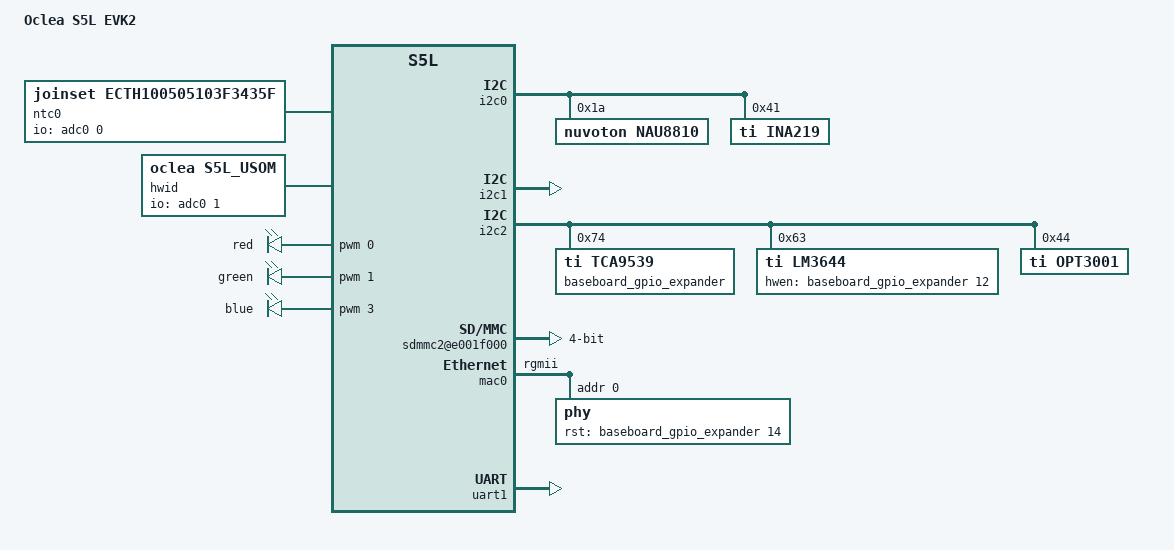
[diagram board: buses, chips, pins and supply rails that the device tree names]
/dts-v1/;
/include/ "ambarella-s5l.dtsi"
/include/ "s5l_oclea_cma.dtsi"
/include/ "s5l_oclea_private_evk2.dtsi"
/ {
 model = "Oclea S5L EVK2";
 compatible = "ambarella,s5l_oclea", "ambarella,s5l";
 oclea-vin-version = <1>;
 chosen {
  bootargs = "console=ttyS0 noinitrd root=##ROOT_DEVICE## rw rootfstype=ext4 rootwait init=/sbin/init";
 };
 apb@e8000000 {
  ntc0: ntc0 {
   compatible = "joinset,ecth100505103f3435f";
   pullup-uv = <3300000>;
   pullup-ohm = <10000>;
   pulldown-ohm = <0>;
   io-channels = <&adc0 0>;
   alias-name = "main-ntc";
   #thermal-sensor-cells = <0>;
  };
  hwid {
   compatible = "oclea,s5l_uSOM";
   pullup-mv = <3300>;
   io-channels = <&adc0 1>;
   alias-name = "hwid";
  };
  adc0: adc@e801d000 {
   amb,channels-used = <0x0a>;
   #io-channel-cells = <1>;
  };
  i2c0: i2c@e8003000 {
   status = "ok";
   nau8810: codec@1a {
    compatible = "nuvoton,nau8810";
    #sound-dai-cells = <0>;
    reg = <0x1a>;
   };
   ina219: ina219@41 {
    compatible = "ti,ina219";
    reg = <0x41>;
    shunt-resistor = <100000>;
   };
  };
  i2c1: i2c@e8001000 {
   status = "ok";
  };
  i2c2: i2c@e8007000 {
   status = "ok";
   baseboard_gpio_expander: tca9539@74 {
    compatible = "ti,tca9539";
    reg = <0x74>;
    gpio-controller;
    interrupt-parent = <&gpio>;
    interrupt-controller;
    #gpio-cells = <2>;
    gpio-line-names =
     "", "", "", "", "", "", "", "",
     "", "bt-en", "", "ir-led-gpio", "ir-led-en", "rs485-re", "eth-reset", "";
    port-0-0 {
     gpios = <0 0>;
     output-low;
    };
    port-0-1 {
     gpios = <1 0>;
     output-low;
    };
    port-0-2 {
     gpios = <2 0>;
     output-low;
    };
    port-0-3 {
     gpios = <3 0>;
     output-low;
    };
    port-0-4 {
     gpios = <4 0>;
     output-low;
    };
    port-0-5 {
     gpios = <5 0>;
     output-low;
    };
    port-0-6 {
     gpios = <6 0>;
     output-low;
    };
    port-0-7 {
     gpios = <7 0>;
     output-low;
    };
    port-1-0 {
     gpios = <8 0>;
     output-low;
    };
    port-1-1 {
     gpios = <9 0>;
     output-low;
    };
    port-1-2 {
     gpios = <10 0>;
     output-low;
    };
    port-1-3 {
     gpios = <11 0>;
     output-low;
    };
    port-1-4 {
     gpios = <12 0>;
     output-low;
    };
    port-1-5 {
     gpios = <13 0>;
     output-low;
    };
    port-1-6 {
     gpios = <14 0>;
     output-low;
    };
    port-1-7 {
     gpios = <15 0>;
     output-low;
    };
   };
   lm3644: ir_led@63 {
    compatible = "ti,lm3644";
    reg = <0x63>;
    lm3644,hwen-gpio = <&baseboard_gpio_expander 12 0>;
    lm3644,flash-timeout = <0x1>;
    lm3644,pass-mode;
    lm3644,disable-tx;
   };
   opt3001@44 {
    compatible = "ti,opt3001";
    reg = <0x44>;
   };
  };
  ir@e8006000 {
   status = "disabled";
  };
  pwm: pwm@e8008000 {
   pinctrl-names = "default";
   pinctrl-0 = <&pwm0_pins_b>, <&pwm1_pins_c>, <&pwm3_pins_c>;
  };
  pinctrl: pinctrl@e8009000 {
   enet_2nd_ref_clk_pin: enet_2nd_ref_clk@0 {
     reg = <0>;
     amb,pinmux-ids = <0x1044>;
   };
   sdmmc2_rst_pin: sdmmc2_rst@0 {
    reg = <0>;
    amb,pinmux-ids = <0x2070>;
   };
  };
 };
 ahb@e0000000 {
  sdmmc0@e0002000 {
   amb,emmc-boot;
   amb,sd-force-1_8v;
   amb,fixed-cd = <1>;
  };
  sdmmc2@e001f000 {
   status = "ok";
   pinctrl-0 = <&sdmmc2_pins_4bit &sdmmc2_cd_pin &sdmmc2_rst_pin>;
   bus-width = <4>;
   no-1-8-v;
  };
  mac0: ethernet@e000e000 {
   amb,tx-clk-invert;
   amb,override-phy-type;
   pinctrl-0 = <&rgmii_pins &rgmii_mdio_pins &enet_2nd_ref_clk_pin>;
   phy-mode = "rgmii";
   phy@0 {
    reg = <0>;
    rst-gpios = <&baseboard_gpio_expander 14 0>;
    rst-gpio-delay = <100>;
   };
  };
  nand0: nand@e0001000 {
   status = "disabled";
  };
  spi0: spi@e0020000 {
   status = "disabled";
  };
  spi2: spi@e0022000 {
   status = "disabled";
  };
  uart1: uart@e0032000 {
      status = "ok";
  };
  hdmi@e0013000 {
   amb,i2c-adapter = <1>;
   pinctrl-names = "default";
   pinctrl-0 = <&hdmi_pin>;
  };
 };
 pwm-leds {
        compatible = "pwm-leds";
        red {
            label = "red";
            pwms = <&pwm 0 40000 0>;
            max-brightness = <255>;
        };
        green {
            label = "green";
            pwms = <&pwm 1 40000 0>;
            max-brightness = <255>;
        };
        blue {
            label = "blue";
            pwms = <&pwm 3 40000 0>;
            max-brightness = <255>;
        };
    };
 rct@ec170000 {
  usbphy: usbphy@ec170050 {
   amb,ocp-polarity = <1>;
   amb,phy-route = "device";
   pinctrl-names = "default";
   pinctrl-0 = <&usb_host0_pins>;
   md-gpios = <&gpio 13 0x0>;
  };
 };
 iav {
  vinc0 {
  };
  vinc1 {
  };
  hwtimer {
   compatible = "ambarella,hwtimer";
   interrupts = <0 3 0x1>;
   interrupt-names = "hwtimer";
  };
 };
 sound {
  compatible = "ambarella,audio-board","simple-audio-card";
  simple-audio-card,name = "nau8810 @ AMBEVK";
  simple-audio-card,mclk-fs = <256>;
  simple-audio-card,widgets =
  "Speaker", "Speaker";
  simple-audio-card,routing =
  "Speaker", "SPKOUTP",
  "Speaker", "SPKOUTN";
  simple-audio-card,dai-link@0 {
   format = "i2s";
   cpu {
    sound-dai = <&i2s0>;
   };
   codec {
    sound-dai = <&nau8810>;
   };
  };
 };
 clocks {
  gclk_vo: gclk-vo {
   assigned-clock-rates = <0> ;
  };
 };
 thermal-zones {
  soc_thermal: soc-thermal {
   polling-delay-passive = <250>;
   polling-delay = <1000>;
   thermal-sensors = <&ntc0>;
   trips {
    soc_alert: soc-alert {
     temperature = <80000>;
     hysteresis = <1000>;
     type = "passive";
    };
    soc_crit: soc-crit {
     temperature = <85000>;
     hysteresis = <1000>;
     type = "critical";
    };
   };
  };
 };
};
